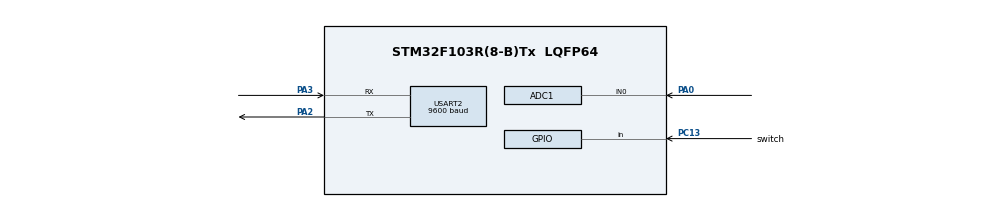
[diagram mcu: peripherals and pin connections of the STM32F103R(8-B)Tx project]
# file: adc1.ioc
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ADC1.Channel-0\#ChannelRegularConversion=ADC_CHANNEL_0
ADC1.NbrOfConversionFlag=1
ADC1.Rank-0\#ChannelRegularConversion=1
ADC1.SamplingTime-0\#ChannelRegularConversion=ADC_SAMPLETIME_1CYCLE_5
ADC1.master=1
Mcu.Family=STM32F1
Mcu.Name=STM32F103R(8-B)Tx
Mcu.Package=LQFP64
NVIC.PriorityGroup=NVIC_PRIORITYGROUP_4
NVIC.USART2_IRQn=true\:0\:0\:false\:false\:true\:true
PA0-WKUP.Signal=ADCx_IN0
PA2.Mode=Asynchronous
PA2.Signal=USART2_TX
PA3.Mode=Asynchronous
PA3.Signal=USART2_RX
PC13-TAMPER-RTC.GPIO_Label=switch
PC13-TAMPER-RTC.Signal=GPIO_Input
ProjectManager.HeapSize=0x200
ProjectManager.StackSize=0x400
ProjectManager.TargetToolchain=MDK-ARM V5
RCC.APB1Freq_Value=8000000
RCC.APB2Freq_Value=8000000
SH.ADCx_IN0.0=ADC1_IN0,IN0
USART2.BaudRate=9600
USART2.VirtualMode=VM_ASYNC
VP_SYS_VS_ND.Mode=No_Debug
board=adc1

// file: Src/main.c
#include "main.h"
#include "stm32f1xx_hal.h"

ADC_HandleTypeDef hadc1;

UART_HandleTypeDef huart2;

/* USER CODE BEGIN PV */
/* Private variables ---------------------------------------------------------*/

/* USER CODE END PV */

void SystemClock_Config(void);
static void MX_GPIO_Init(void);
static void MX_ADC1_Init(void);
static void MX_USART2_UART_Init(void);

/* USER CODE BEGIN PFP */
/* Private function prototypes -----------------------------------------------*/

/* USER CODE END PFP */

/* USER CODE BEGIN 0 */
int fputc(int ch, FILE *f)
{
	uint8_t temp[1] = {ch} ;

	HAL_UART_Transmit(&huart2, temp, 1, 50) ;

	return(ch) ;
}
/* USER CODE END 0 */

int main(void)
{

  /* MCU Configuration----------------------------------------------------------*/

  /* Reset of all peripherals, Initializes the Flash interface and the Systick. */
  HAL_Init();

  /* Configure the system clock */
  SystemClock_Config();

  /* Initialize all configured peripherals */
  MX_GPIO_Init();
  MX_ADC1_Init();
  MX_USART2_UART_Init();
  /* USER CODE BEGIN 2 */
	uint16_t adcValue ;
	uint8_t pin_state ;
  /* USER CODE END 2 */

  /* Infinite loop */
  while (1)
  {

  /* USER CODE BEGIN 3 */
	pin_state = HAL_GPIO_ReadPin(switch_GPIO_Port, switch_Pin) ;

	HAL_ADC_Start(&hadc1);  // start using ADC
	HAL_ADC_PollForConversion(&hadc1, 100) ;  //set adc address and time out value
	adcValue = HAL_ADC_GetValue(&hadc1) ;  // get adc value

	if (!pin_state)
	{
		printf("adc : %d\n", adcValue) ;
	}

	HAL_Delay(1000) ;
  }
  /* USER CODE END 3 */

}

void SystemClock_Config(void)
{

  RCC_OscInitTypeDef RCC_OscInitStruct;
  RCC_ClkInitTypeDef RCC_ClkInitStruct;
  RCC_PeriphCLKInitTypeDef PeriphClkInit;

    /**Initializes the CPU, AHB and APB busses clocks
    */
  RCC_OscInitStruct.OscillatorType = RCC_OSCILLATORTYPE_HSI;
  RCC_OscInitStruct.HSIState = RCC_HSI_ON;
  RCC_OscInitStruct.HSICalibrationValue = 16;
  RCC_OscInitStruct.PLL.PLLState = RCC_PLL_NONE;
  if (HAL_RCC_OscConfig(&RCC_OscInitStruct) != HAL_OK)
  {
    _Error_Handler(__FILE__, __LINE__);
  }

    /**Initializes the CPU, AHB and APB busses clocks
    */
  RCC_ClkInitStruct.ClockType = RCC_CLOCKTYPE_HCLK|RCC_CLOCKTYPE_SYSCLK
                              |RCC_CLOCKTYPE_PCLK1|RCC_CLOCKTYPE_PCLK2;
  RCC_ClkInitStruct.SYSCLKSource = RCC_SYSCLKSOURCE_HSI;
  RCC_ClkInitStruct.AHBCLKDivider = RCC_SYSCLK_DIV1;
  RCC_ClkInitStruct.APB1CLKDivider = RCC_HCLK_DIV1;
  RCC_ClkInitStruct.APB2CLKDivider = RCC_HCLK_DIV1;

  if (HAL_RCC_ClockConfig(&RCC_ClkInitStruct, FLASH_LATENCY_0) != HAL_OK)
  {
    _Error_Handler(__FILE__, __LINE__);
  }

  PeriphClkInit.PeriphClockSelection = RCC_PERIPHCLK_ADC;
  PeriphClkInit.AdcClockSelection = RCC_ADCPCLK2_DIV2;
  if (HAL_RCCEx_PeriphCLKConfig(&PeriphClkInit) != HAL_OK)
  {
    _Error_Handler(__FILE__, __LINE__);
  }

    /**Configure the Systick interrupt time
    */
  HAL_SYSTICK_Config(HAL_RCC_GetHCLKFreq()/1000);

    /**Configure the Systick
    */
  HAL_SYSTICK_CLKSourceConfig(SYSTICK_CLKSOURCE_HCLK);

  /* SysTick_IRQn interrupt configuration */
  HAL_NVIC_SetPriority(SysTick_IRQn, 0, 0);
}

/* ADC1 init function */
static void MX_ADC1_Init(void)
{

  ADC_ChannelConfTypeDef sConfig;

    /**Common config
    */
  hadc1.Instance = ADC1;
  hadc1.Init.ScanConvMode = ADC_SCAN_DISABLE;
  hadc1.Init.ContinuousConvMode = DISABLE;
  hadc1.Init.DiscontinuousConvMode = DISABLE;
  hadc1.Init.ExternalTrigConv = ADC_SOFTWARE_START;
  hadc1.Init.DataAlign = ADC_DATAALIGN_RIGHT;
  hadc1.Init.NbrOfConversion = 1;
  if (HAL_ADC_Init(&hadc1) != HAL_OK)
  {
    _Error_Handler(__FILE__, __LINE__);
  }

    /**Configure Regular Channel
    */
  sConfig.Channel = ADC_CHANNEL_0;
  sConfig.Rank = ADC_REGULAR_RANK_1;
  sConfig.SamplingTime = ADC_SAMPLETIME_1CYCLE_5;
  if (HAL_ADC_ConfigChannel(&hadc1, &sConfig) != HAL_OK)
  {
    _Error_Handler(__FILE__, __LINE__);
  }

}

/* USART2 init function */
static void MX_USART2_UART_Init(void)
{

  huart2.Instance = USART2;
  huart2.Init.BaudRate = 9600;
  huart2.Init.WordLength = UART_WORDLENGTH_8B;
  huart2.Init.StopBits = UART_STOPBITS_1;
  huart2.Init.Parity = UART_PARITY_NONE;
  huart2.Init.Mode = UART_MODE_TX_RX;
  huart2.Init.HwFlowCtl = UART_HWCONTROL_NONE;
  huart2.Init.OverSampling = UART_OVERSAMPLING_16;
  if (HAL_UART_Init(&huart2) != HAL_OK)
  {
    _Error_Handler(__FILE__, __LINE__);
  }

}

/** Configure pins as
        * Analog
        * Input
        * Output
        * EVENT_OUT
        * EXTI
*/
static void MX_GPIO_Init(void)
{

  GPIO_InitTypeDef GPIO_InitStruct;

  /* GPIO Ports Clock Enable */
  __HAL_RCC_GPIOC_CLK_ENABLE();
  __HAL_RCC_GPIOA_CLK_ENABLE();

  /*Configure GPIO pin : switch_Pin */
  GPIO_InitStruct.Pin = switch_Pin;
  GPIO_InitStruct.Mode = GPIO_MODE_INPUT;
  GPIO_InitStruct.Pull = GPIO_NOPULL;
  HAL_GPIO_Init(switch_GPIO_Port, &GPIO_InitStruct);

}

void _Error_Handler(char *file, int line)
{
  while(1)
  {
  }
}

/************************ (C) COPYRIGHT STMicroelectronics *****END OF FILE****/
